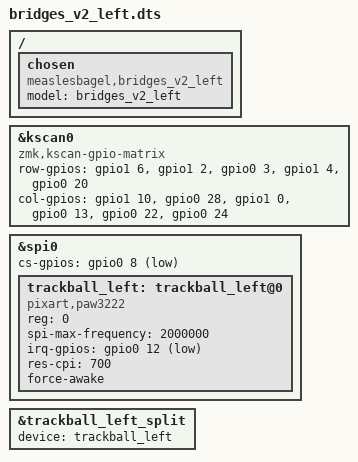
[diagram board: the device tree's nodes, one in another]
/*
 * Copyright (c) 2026 Vincent Franco
 * SPDX-License-Identifier: MIT
 */

#include "bridges_v2.dts"

/* This half carries the left trackball. Configs can test for it to attach
 * settings that need the local sensor node. */
#define BRIDGES_V2_LEFT_TRACKBALL 1

/ {
  chosen {
    model = "bridges_v2_left";
    compatible = "measlesbagel,bridges_v2_left";
  };
};

&kscan0 {
  compatible = "zmk,kscan-gpio-matrix";

  row-gpios
    = <&gpio1 6 (GPIO_ACTIVE_HIGH | GPIO_PULL_DOWN)>
    , <&gpio1 2 (GPIO_ACTIVE_HIGH | GPIO_PULL_DOWN)>
    , <&gpio0 3 (GPIO_ACTIVE_HIGH | GPIO_PULL_DOWN)>
    , <&gpio1 4 (GPIO_ACTIVE_HIGH | GPIO_PULL_DOWN)>
    , <&gpio0 20 (GPIO_ACTIVE_HIGH | GPIO_PULL_DOWN)>
    ;

  col-gpios
    = <&gpio1 10 GPIO_ACTIVE_HIGH>
    , <&gpio0 28 GPIO_ACTIVE_HIGH>
    , <&gpio1 0 GPIO_ACTIVE_HIGH>
    , <&gpio0 13 GPIO_ACTIVE_HIGH>
    , <&gpio0 22 GPIO_ACTIVE_HIGH>
    , <&gpio0 24 GPIO_ACTIVE_HIGH>
    ;
};

&spi0 {
    cs-gpios = <&gpio0 8 GPIO_ACTIVE_LOW>;

    trackball_left: trackball_left@0 {
        status = "okay";
        compatible = "pixart,paw3222";
        reg = <0>;
        spi-max-frequency = <2000000>;
        irq-gpios = <&gpio0 12 GPIO_ACTIVE_LOW>;
        res-cpi = <700>;
        force-awake;
    };
};

/* Send this ball's motion on the left channel when another device is
 * central. On a central left half the channel is unused. */
&trackball_left_split {
    status = "okay";
    device = <&trackball_left>;
};
